# STM32U585 register map
File version: 2.2
CPU: CM33 r0p1, little endian, MPU, FPU, 4 interrupt priority bits
Registers are 32-bit, read-write, reset 0x0 unless marked. A register's access mark holds for its fields unless they carry their own. Offsets are from the block's base; [hi:lo] are bit positions; {n}, {i} and the like mark numbered series.

## EXTI — External interrupt/event
Base 0x46022000
Same registers: SEC_EXTI 0x56022000
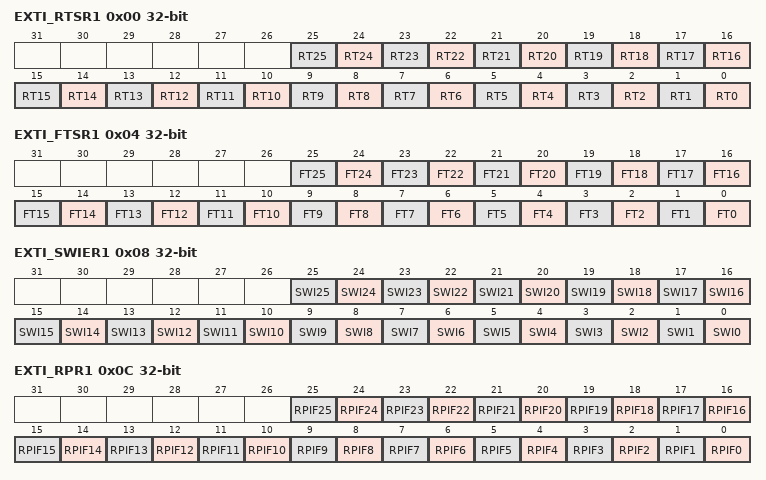
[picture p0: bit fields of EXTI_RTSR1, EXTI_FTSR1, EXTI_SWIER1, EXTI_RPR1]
0x00 EXTI_RTSR1 — EXTI rising trigger selection register
  [all] fields
    0=Rising trigger disabled (for event and interrupt) for input line; 1=Rising trigger enabled (for event and interrupt) for input line
  [n] RT{n} (n=0..25) — Rising trigger event configuration bit of configurable event input x
0x04 EXTI_FTSR1 — EXTI falling trigger selection register
  [all] fields
    0=Falling trigger disabled (for event and interrupt) for input line; 1=Falling trigger enabled (for event and interrupt) for input line
  [n] FT{n} (n=0..25) — Falling trigger event configuration bit of configurable event input x
0x08 EXTI_SWIER1 — EXTI software interrupt event register
  [all] fields
    0=Writing 0 has no effect; 1=Writing 1 triggers a rising edge event on event x. This bit is auto cleared by hardware.
  [n] SWI{n} (n=0..25) — Software interrupt on event x
0x0C EXTI_RPR1 — EXTI rising edge pending register
  [all] fields
    0=No rising edge trigger request occurred; 1=Rising edge trigger request occurred
  [n] RPIF{n} (n=0..25) — configurable event inputs x rising edge pending bit
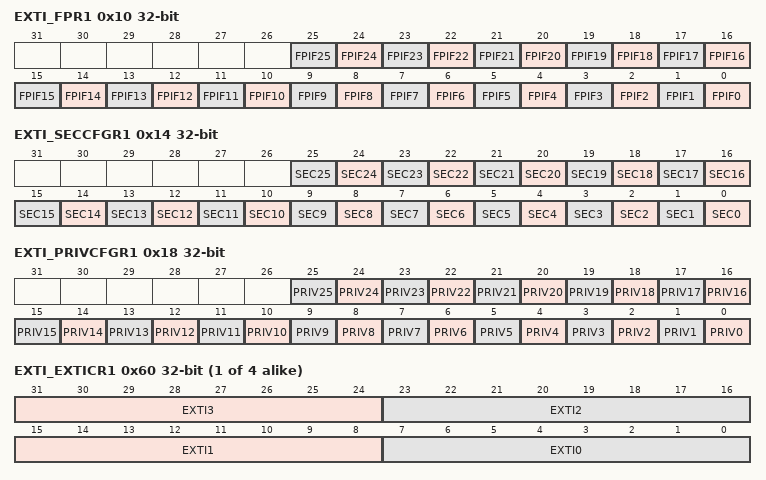
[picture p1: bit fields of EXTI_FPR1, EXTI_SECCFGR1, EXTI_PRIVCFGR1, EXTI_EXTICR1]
0x10 EXTI_FPR1 — EXTI falling edge pending register
  [all] fields
    0=No falling edge trigger request occurred; 1=Falling edge trigger request occurred
  [n] FPIF{n} (n=0..25) — configurable event inputs x falling edge pending bit
0x14 EXTI_SECCFGR1 — EXTI security configuration register
  [all] fields
    0=Event security disabled (non-secure); 1=Event security enabled (secure)
  [n] SEC{n} (n=0..25) — Security enable on event input x
0x18 EXTI_PRIVCFGR1 — EXTI privilege configuration register
  [all] fields
    0=Event privilege disabled (unprivileged); 1=Event privilege enabled (privileged)
  [n] PRIV{n} (n=0..25) — Security enable on event input x
{0x5C+4i} EXTI_EXTICR{i} (i=1..4) — EXTI external interrupt selection register
  [31:24] EXTI{4i-1} — EXTIm+3 GPIO port selection
  [23:16] EXTI{4i-2} — EXTIm+2 GPIO port selection
  [15:8] EXTI{4i-3} — EXTIm+1 GPIO port selection
  [7:0] EXTI{4i-4} — EXTIm GPIO port selection
0x70 EXTI_LOCKR — EXTI lock register
  [0] LOCK — Global security and privilege configuration registers (EXTI_SECCFGR and EXTI_PRIVCFGR) lock
    0=Security and privilege configuration open, can be modified; 1=Security and privilege configuration locked, can no longer be modified
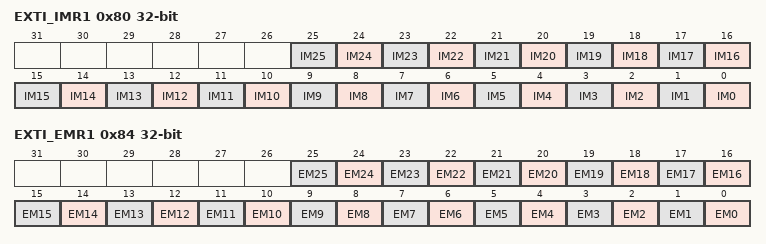
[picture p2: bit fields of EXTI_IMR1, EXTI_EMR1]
0x80 EXTI_IMR1 — EXTI CPU wake-up with interrupt mask register
  [all] fields
    0=Wake-up with interrupt request from input event x is masked; 1=Wake-up with interrupt request from input event x is unmasked
  [n] IM{n} (n=0..25) — CPU wake-up with interrupt mask on event input x
0x84 EXTI_EMR1 — EXTI CPU wake-up with event mask register
  [all] fields
    0=Wake-up with event generation from line x is masked; 1=Wake-up with event generation from line x is unmasked
  [n] EM{n} (n=0..25) — CPU wake-up with event generation mask on event input x

## ICache
Base 0x40030400
Same registers: SEC_ICache 0x50030400
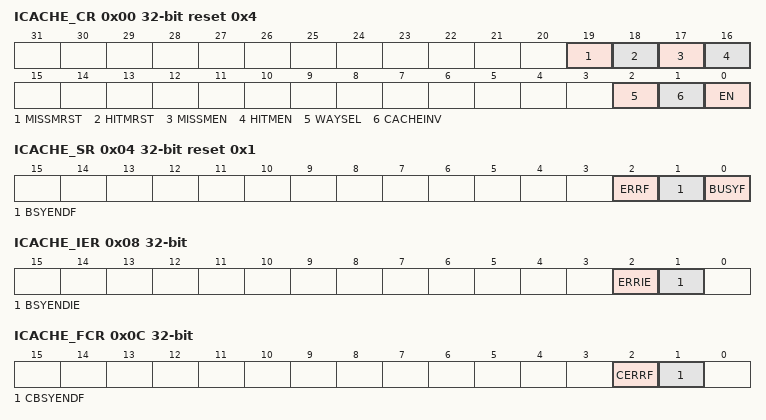
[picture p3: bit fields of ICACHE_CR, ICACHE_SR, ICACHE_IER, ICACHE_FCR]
0x00 ICACHE_CR access per field reset 0x4 — ICACHE control register
  [19] MISSMRST rw, [18] HITMRST rw, [17] MISSMEN rw, [16] HITMEN rw, [2] WAYSEL rw, [1] CACHEINV wo, [0] EN rw
0x04 ICACHE_SR ro reset 0x1 — ICACHE status register
  [2] ERRF, [1] BSYENDF, [0] BUSYF
0x08 ICACHE_IER — ICACHE interrupt enable
  [2] ERRIE, [1] BSYENDIE
0x0C ICACHE_FCR wo — ICACHE flag clear register
  [2] CERRF, [1] CBSYENDF
0x10 ICACHE_HMONR ro — ICACHE hit monitor register
  [31:0] HITMON
0x14 ICACHE_MMONR ro — ICACHE miss monitor register
  [15:0] MISSMON
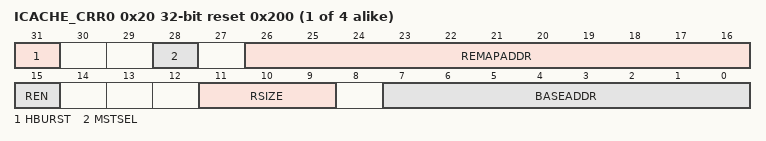
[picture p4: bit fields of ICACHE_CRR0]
{0x20+4i} ICACHE_CRR{i} reset 0x200 (i=0..3) — ICACHE region configuration
  [31] HBURST, [28] MSTSEL, [26:16] REMAPADDR, [15] REN, [11:9] RSIZE, [7:0] BASEADDR

## Notices in the file
Copyright (c) 2025 STMicroelectronics.
SPDX-License-Identifier: Apache-2.0
Licensed under the Apache License, Version 2.0 (the "License");
you may not use this file except in compliance with the License.
You may obtain a copy of the License at
http://www.apache.org/licenses/LICENSE-2.0
Unless required by applicable law or agreed to in writing, software
distributed under the License is distributed on an "AS IS" BASIS,
WITHOUT WARRANTIES OR CONDITIONS OF ANY KIND, either express or implied.
See the License for the specific language governing permissions and
limitations under the License.
